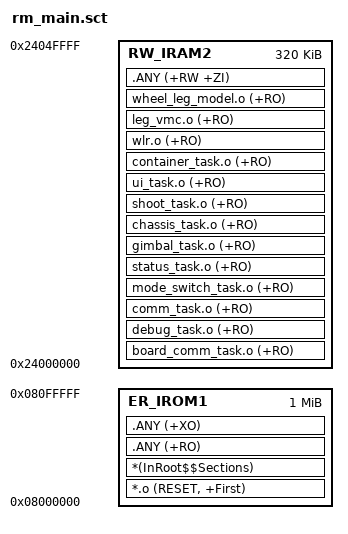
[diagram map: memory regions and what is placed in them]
; *************************************************************
; *** Scatter-Loading Description File generated by uVision ***
; *************************************************************

LR_IROM1 0x08000000 0x00100000  {    ; load region size_region
  ER_IROM1 0x08000000 0x00100000  {  ; load address = execution address
   *.o (RESET, +First)
   *(InRoot$$Sections)
   .ANY (+RO)
   .ANY (+XO)
  }
  RW_IRAM2 0x24000000 0x00050000  {  ; RW data
    board_comm_task.o (+RO)
    debug_task.o (+RO)
    comm_task.o (+RO)
    mode_switch_task.o (+RO)
    status_task.o (+RO)
    gimbal_task.o (+RO)
    chassis_task.o (+RO)
    shoot_task.o (+RO)
    ui_task.o (+RO)
    container_task.o (+RO)
    wlr.o (+RO)
    leg_vmc.o (+RO)
    wheel_leg_model.o (+RO)
   .ANY (+RW +ZI)
  }
}

